# MU3E_DBG_MM2RUNCTRL register map
Vendor: Mu3e; Series: MU3E_FPGA_IP; File version: 1.0.0
CSR-driven local run-control source used by FEB datapath bring-up.
Registers are 32-bit, read-only, reset 0x0 unless marked. A register's access mark holds for its fields unless they carry their own. Offsets are from the block's base; lines under a group give offsets from that group; [hi:lo] are bit positions; {n}, {i} and the like mark numbered series; 'fields as' and 'values as' point back to an identical list; <NAME> marks a mode.

## Memory map
0x00000000 DBG_MM2RUNCTRL_CSR size 0x40 — Relative 16-word Avalon-MM CSR aperture for local run-control command injection.

## DBG_MM2RUNCTRL_CSR — Relative 16-word Avalon-MM CSR aperture for local run-control command injection.
Base 0x00000000
0x00 ID reset 0x4D325243 — IP identifier, ASCII M2RC.
  [31:0] id — ASCII M2RC identifier.
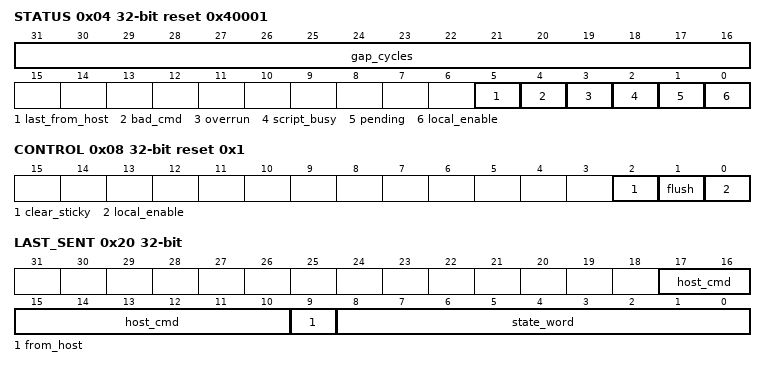
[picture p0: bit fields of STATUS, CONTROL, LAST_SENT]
0x04 STATUS reset 0x40001 — Current local source state and sticky error flags.
  [31:16] gap_cycles — Configured script inter-command gap in clock cycles.
  [5] last_from_host — Last accepted command was written through HOST_CMD rather than STATE_CMD.
  [4] bad_cmd — Sticky flag set when software wrote an unsupported command encoding.
  [3] overrun — Sticky flag set when software wrote a command while the source could not accept it.
  [2] script_busy — A built-in command script is active.
  [1] pending — A run-control word is pending on the Avalon-ST output.
  [0] local_enable — Local CSR command source is enabled.
0x08 CONTROL rw reset 0x1 — Local source enable plus write-one pulses for flush and sticky-flag clear.
  [2] clear_sticky wo — Write one to clear overrun and bad_cmd sticky flags.
  [1] flush wo — Write one to clear pending/script state.
  [0] local_enable — When set, CSR writes can enqueue local run-control words.
0x0C HOST_CMD wo — Write a raw host command byte. Accepted values include 0x10..0x14 and 0x30..0x33.
  [7:0] host_cmd — Host command byte decoded to a one-hot run-control state.
0x10 STATE_CMD wo — Write a direct one-hot run-control state word.
  [8:0] state_word — One-hot run-control state bits [8:0].
0x14 SCRIPT wo — Launch a built-in local run-control script.
  [2:0] script_kind — 1=self-run, 2=end-run, 3=abort-to-idle.
0x18 GAP_CYCLES rw reset 0x40000 — Script inter-command gap. RTL writes and reads this value in bits [31:16].
  [31:16] gap_cycles — Inter-command gap for SCRIPT sequencing.
0x1C SENT_COUNT — Accepted Avalon-ST command count.
  [31:0] value — Saturating-free 32-bit accepted-command counter.
0x20 LAST_SENT — Last accepted output command image.
  [17:10] host_cmd — Raw host command byte for the last command.
  [9] from_host — Last command originated from HOST_CMD decode.
  [8:0] state_word — One-hot run-control state bits.
